# cslr_smcp register map
Vendor: Texas Instruments
Peripheral module from a debugger description file (folder c6472).
Registers are 32-bit, read-only, reset 0x0 unless marked. A register's access mark holds for its fields unless they carry their own. Offsets are as the file gives them; lines under a group give offsets from that group; [hi:lo] are bit positions; {n}, {i} and the like mark numbered series; 'fields as' and 'values as' point back to an identical list; <NAME> marks a mode.

## SMCP — Shared Memory Controller Profiler
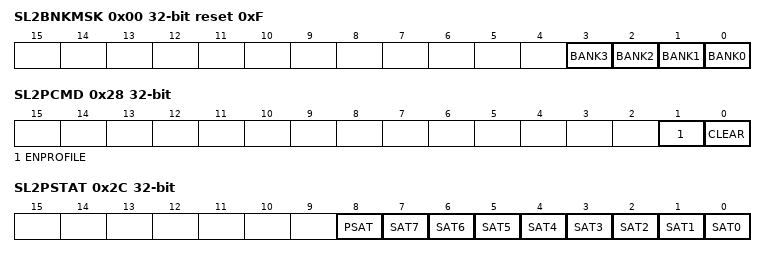
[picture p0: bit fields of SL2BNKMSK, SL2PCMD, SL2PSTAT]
0x00 SL2BNKMSK access not given reset 0xF — SMC Bank Mask Register
  [n] BANK{n} rw (n=0..3) — PAGE{n+27} Prefetch Enable
{0x4+4i} SL2PWSCNT{i} (i=0..7) — SMC Wait State Counter
  [31:0] WSCNT — 32 bit counters for n wait state read accesses
0x24 SL2PFCCNT — SMC Prefetch Counter
  [31:0] PFCCNT — 32 bit prefetch counter
0x28 SL2PCMD access not given — SMC Memory Protection Fault Address Register
  [1] ENPROFILE rw — Enable/Disable Profile
  [0] CLEAR rw — Clear all the counters
0x2C SL2PSTAT access not given — SMC Profiler Counter Saturation status
  [8] PSAT ro — SL2PFCCNT Counter Saturates
  [n] SAT{n} ro (n=0..7) — SL2PWSCNT{n} counter saturates
0x30 SL2STATMASK access not given — SMC Atomic access monitor Status
  [n] MASK_WS{n} rw (n=4..7) — MASK_WS{n} = 1, COMBINE WS{n}_EVENT to generate SMC Profile event to GEM, otherwise not to combine WS{n}_event to generate SMC profile event to GEM
  [n+4] MASK_WS{n} rw (n=0..3) — MASK_WS{n} = 1, COMBINE WS{n}_EVENT to generate SMC Profile event to GEM, otherwise not to combine WS{n}_event to generate SMC profile event to GEM
  [3:0] Reserved — (access N)
